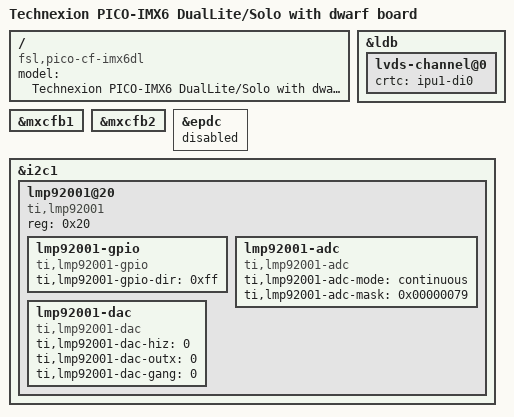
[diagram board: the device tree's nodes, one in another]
/*
 * Copyright 2016 Technexion Ltd.
 *
 * Author: Wig Cheng <wig.cheng@technexion.com>
 *	   Richard Hu <richard.hu@technexion.com>
 *	   Tapani Utriainen <tapani@technexion.com>
 *
 * This program is free software; you can redistribute it and/or modify
 * it under the terms of the GNU General Public License version 2 as
 * published by the Free Software Foundation.
 *
 */
/dts-v1/;

#include <dt-bindings/interrupt-controller/irq.h>
#include "imx6dl.dtsi"
#include "imx6qdl-pico.dtsi"
#include "baseboard_pico_dwarf.dtsi"
/ {
	model = "Technexion PICO-IMX6 DualLite/Solo with dwarf board";
	compatible = "fsl,pico-cf-imx6dl", "fsl,imx6dl";
};

&ldb {
	lvds-channel@0 {
		crtc = "ipu1-di0";
	};
};

&mxcfb1 {
	status = "okay";
};

&mxcfb2 {
	status = "okay";
};

#if 0
&mxcfb3 {
	status = "okay";
};

&mxcfb4 {
	status = "okay";
};
#endif

&epdc {
	status = "disabled";
};

&i2c1 {
	lmp92001@20 {
		compatible = "ti,lmp92001";
		reg = <0x20>;
		lmp92001-gpio {
                        compatible = "ti,lmp92001-gpio";
                        ti,lmp92001-gpio-dir = /bits/ 8 <0xff>;
		};
		lmp92001-adc {
                        compatible = "ti,lmp92001-adc";
                        ti,lmp92001-adc-mode = "continuous";
                        ti,lmp92001-adc-mask = <0x00000079>;
		};
	        lmp92001-dac {
                        compatible = "ti,lmp92001-dac";
                        ti,lmp92001-dac-hiz  = /bits/ 8 <0>;
                        ti,lmp92001-dac-outx = /bits/ 8 <0>;
                        ti,lmp92001-dac-gang = /bits/ 8 <0>;
                };
	};
};
